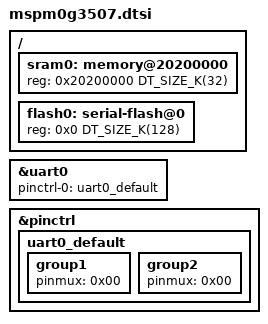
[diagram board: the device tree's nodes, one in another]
/*
 * SPDX-License-Identifier: Apache-2.0
 */

#include <mem.h>
#include <ti/mspm0g350x.dtsi>

/ {
	sram0: memory@20200000 {
		reg = <0x20200000 DT_SIZE_K(32)>;
	};

	flash0: serial-flash@0 {
		reg = <0x0 DT_SIZE_K(128)>;
	};
};

&uart0 {
    pinctrl-0 = <&uart0_default>;
	pinctrl-names = "default";
};

&pinctrl {
    status = "okay";
    uart0_default: uart0_default {
        group1 {
            pinmux = <0x00>;
        };
        group2 {
            pinmux = <0x00>;
            /* input-enable; */
        };
    };
};
